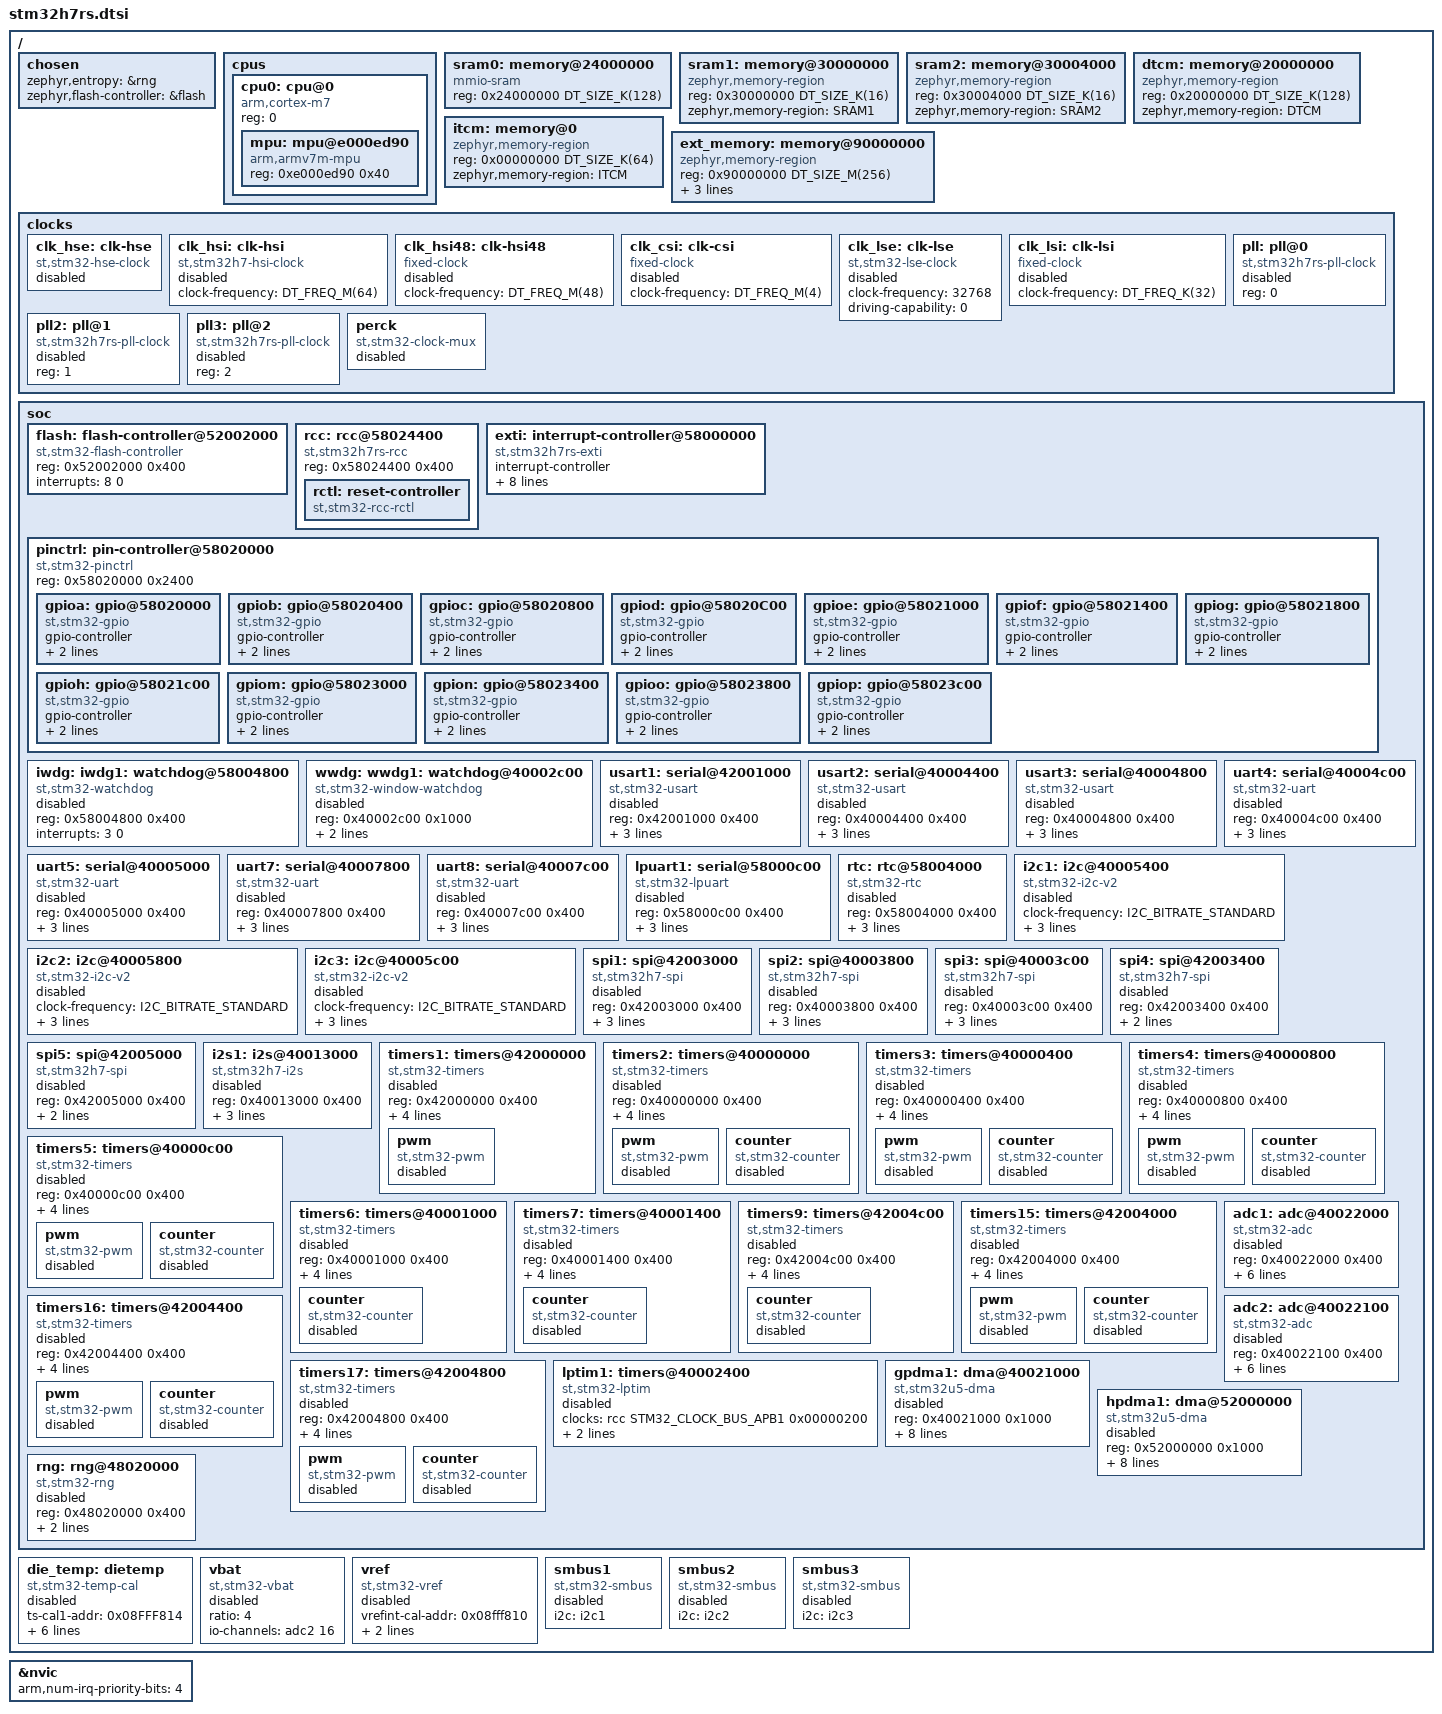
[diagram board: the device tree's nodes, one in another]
/*
 * Copyright (c) 2024 STMicroelectronics
 *
 * SPDX-License-Identifier: Apache-2.0
 */

#include <arm/armv7-m.dtsi>
#include <zephyr/dt-bindings/clock/stm32h7rs_clock.h>
#include <zephyr/dt-bindings/gpio/gpio.h>
#include <zephyr/dt-bindings/i2c/i2c.h>
#include <zephyr/dt-bindings/pwm/pwm.h>
#include <zephyr/dt-bindings/pwm/stm32_pwm.h>
#include <zephyr/dt-bindings/dma/stm32_dma.h>
#include <zephyr/dt-bindings/adc/stm32h7_adc.h>
#include <zephyr/dt-bindings/reset/stm32h7_reset.h>
#include <zephyr/dt-bindings/adc/adc.h>
#include <zephyr/dt-bindings/memory-controller/stm32-fmc-sdram.h>
#include <zephyr/dt-bindings/memory-attr/memory-attr.h>
#include <zephyr/dt-bindings/memory-attr/memory-attr-arm.h>
#include <freq.h>

/*
 * STM32H7RS line contains has many common peripherals with STM32H7.
 */

/ {
	chosen {
		zephyr,entropy = &rng;
		zephyr,flash-controller = &flash;
	};

	cpus {
		#address-cells = <1>;
		#size-cells = <0>;

		cpu0: cpu@0 {
			device_type = "cpu";
			compatible = "arm,cortex-m7";
			reg = <0>;
			#address-cells = <1>;
			#size-cells = <1>;

			mpu: mpu@e000ed90 {
				compatible = "arm,armv7m-mpu";
				reg = <0xe000ed90 0x40>;
			};
		};
	};

	/* System data RAM accessible over AXI bus: AXI SRAM1 in CD domain */
	sram0: memory@24000000 {
		compatible = "mmio-sram";
		reg = <0x24000000 DT_SIZE_K(128)>;
	};

	/* System data RAM accessible over AHB bus: SRAM1 in D2 domain */
	sram1: memory@30000000 {
		reg = <0x30000000 DT_SIZE_K(16)>;
		compatible = "zephyr,memory-region", "mmio-sram";
		zephyr,memory-region = "SRAM1";
	};

	/* System data RAM accessible over AHB bus: SRAM2 in D2 domain */
	sram2: memory@30004000 {
		compatible = "zephyr,memory-region", "mmio-sram";
		reg = <0x30004000 DT_SIZE_K(16)>;
		zephyr,memory-region = "SRAM2";
	};

	dtcm: memory@20000000 {
		compatible = "zephyr,memory-region", "arm,dtcm";
		reg = <0x20000000 DT_SIZE_K(128)>;
		zephyr,memory-region = "DTCM";
	};

	itcm: memory@0 {
		compatible = "zephyr,memory-region", "arm,itcm";
		reg = <0x00000000 DT_SIZE_K(64)>;
		zephyr,memory-region = "ITCM";
	};

	ext_memory: memory@90000000 {
		compatible = "zephyr,memory-region", "mmio-sram";
		reg = <0x90000000 DT_SIZE_M(256)>;
		zephyr,memory-region = "EXTMEM";
		zephyr,memory-attr = <( DT_MEM_ARM(ATTR_MPU_IO) )>;
	};

	clocks {
		#address-cells = <1>;
		#size-cells = <0>;

		clk_hse: clk-hse {
			#clock-cells = <0>;
			compatible = "st,stm32-hse-clock";
			status = "disabled";
		};

		clk_hsi: clk-hsi {
			#clock-cells = <0>;
			compatible = "st,stm32h7-hsi-clock";
			clock-frequency = <DT_FREQ_M(64)>;
			status = "disabled";
		};

		clk_hsi48: clk-hsi48 {
			#clock-cells = <0>;
			compatible = "fixed-clock";
			clock-frequency = <DT_FREQ_M(48)>;
			status = "disabled";
		};

		clk_csi: clk-csi {
			#clock-cells = <0>;
			compatible = "fixed-clock";
			clock-frequency = <DT_FREQ_M(4)>;
			status = "disabled";
		};

		clk_lse: clk-lse {
			#clock-cells = <0>;
			compatible = "st,stm32-lse-clock";
			clock-frequency = <32768>;
			driving-capability = <0>;
			status = "disabled";
		};

		clk_lsi: clk-lsi {
			#clock-cells = <0>;
			compatible = "fixed-clock";
			clock-frequency = <DT_FREQ_K(32)>;
			status = "disabled";
		};

		pll: pll@0 {
			#clock-cells = <0>;
			compatible = "st,stm32h7rs-pll-clock";
			reg = <0>;
			status = "disabled";
		};

		pll2: pll@1 {
			#clock-cells = <0>;
			compatible = "st,stm32h7rs-pll-clock";
			reg = <1>;
			status = "disabled";
		};

		pll3: pll@2 {
			#clock-cells = <0>;
			compatible = "st,stm32h7rs-pll-clock";
			reg = <2>;
			status = "disabled";
		};

		perck: perck {
			#clock-cells = <0>;
			compatible = "st,stm32-clock-mux";
			status = "disabled";
		};
	};

	soc {
		flash: flash-controller@52002000 {
			compatible = "st,stm32-flash-controller", "st,stm32h7-flash-controller";
			reg = <0x52002000 0x400>;
			interrupts = <8 0>;

			#address-cells = <1>;
			#size-cells = <1>;
		};

		rcc: rcc@58024400 {
			compatible = "st,stm32h7rs-rcc";
			#clock-cells = <2>;
			reg = <0x58024400 0x400>;

			rctl: reset-controller {
				compatible = "st,stm32-rcc-rctl";
				#reset-cells = <1>;
			};
		};

		exti: interrupt-controller@58000000 {
			compatible = "st,stm32h7rs-exti", "st,stm32-exti";
			interrupt-controller;
			#interrupt-cells = <1>;
			#address-cells = <1>;
			reg = <0x58000000 0x400>;
			/* SBS for interrupt */
			num-lines = <16>;
			interrupts = <16 0>, <17 0>, <18 0>, <19 0>,
				     <20 0>, <21 0>, <22 0>, <23 0>,
				     <24 0>, <25 0>, <26 0>, <27 0>,
				     <28 0>, <29 0>, <30 0>, <31 0>;
			interrupt-names = "line0", "line1", "line2", "line3",
					  "line4", "line5", "line6", "line7",
					  "line8", "line9", "line10", "line11",
					  "line12", "line13", "line14", "line15";
			line-ranges = <0 1>, <1 1>, <2 1>, <3 1>,
				      <4 1>, <5 1>, <6 1>, <7 1>,
				      <8 1>, <9 1>, <10 1>, <11 1>,
				      <12 1>, <13 1>, <14 1>, <15 1>;
		};

		pinctrl: pin-controller@58020000 {
			compatible = "st,stm32-pinctrl";
			#address-cells = <1>;
			#size-cells = <1>;
			reg = <0x58020000 0x2400>;

			gpioa: gpio@58020000 {
				compatible = "st,stm32-gpio";
				gpio-controller;
				#gpio-cells = <2>;
				reg = <0x58020000 0x400>;
				clocks = <&rcc STM32_CLOCK_BUS_AHB4 0x00000001>;
			};

			gpiob: gpio@58020400 {
				compatible = "st,stm32-gpio";
				gpio-controller;
				#gpio-cells = <2>;
				reg = <0x58020400 0x400>;
				clocks = <&rcc STM32_CLOCK_BUS_AHB4 0x00000002>;
			};

			gpioc: gpio@58020800 {
				compatible = "st,stm32-gpio";
				gpio-controller;
				#gpio-cells = <2>;
				reg = <0x58020800 0x400>;
				clocks = <&rcc STM32_CLOCK_BUS_AHB4 0x00000004>;
			};

			gpiod: gpio@58020C00 {
				compatible = "st,stm32-gpio";
				gpio-controller;
				#gpio-cells = <2>;
				reg = <0x58020C00 0x400>;
				clocks = <&rcc STM32_CLOCK_BUS_AHB4 0x00000008>;
			};

			gpioe: gpio@58021000 {
				compatible = "st,stm32-gpio";
				gpio-controller;
				#gpio-cells = <2>;
				reg = <0x58021000 0x400>;
				clocks = <&rcc STM32_CLOCK_BUS_AHB4 0x00000010>;
			};

			gpiof: gpio@58021400 {
				compatible = "st,stm32-gpio";
				gpio-controller;
				#gpio-cells = <2>;
				reg = <0x58021400 0x400>;
				clocks = <&rcc STM32_CLOCK_BUS_AHB4 0x00000020>;
			};

			gpiog: gpio@58021800 {
				compatible = "st,stm32-gpio";
				gpio-controller;
				#gpio-cells = <2>;
				reg = <0x58021800 0x400>;
				clocks = <&rcc STM32_CLOCK_BUS_AHB4 0x00000040>;
			};

			gpioh: gpio@58021c00 {
				compatible = "st,stm32-gpio";
				gpio-controller;
				#gpio-cells = <2>;
				reg = <0x58021c00 0x400>;
				clocks = <&rcc STM32_CLOCK_BUS_AHB4 0x00000080>;
			};

			gpiom: gpio@58023000 {
				compatible = "st,stm32-gpio";
				gpio-controller;
				#gpio-cells = <2>;
				reg = <0x58023000 0x400>;
				clocks = <&rcc STM32_CLOCK_BUS_AHB4 0x00001000>;
			};

			gpion: gpio@58023400 {
				compatible = "st,stm32-gpio";
				gpio-controller;
				#gpio-cells = <2>;
				reg = <0x58023400 0x400>;
				clocks = <&rcc STM32_CLOCK_BUS_AHB4 0x00002000>;
			};

			gpioo: gpio@58023800 {
				compatible = "st,stm32-gpio";
				gpio-controller;
				#gpio-cells = <2>;
				reg = <0x58023800 0x400>;
				clocks = <&rcc STM32_CLOCK_BUS_AHB4 0x00004000>;
			};

			gpiop: gpio@58023c00 {
				compatible = "st,stm32-gpio";
				gpio-controller;
				#gpio-cells = <2>;
				reg = <0x58023c00 0x400>;
				clocks = <&rcc STM32_CLOCK_BUS_AHB4 0x00008000>;
			};
		};

		iwdg: iwdg1: watchdog@58004800 {
			compatible = "st,stm32-watchdog";
			reg = <0x58004800 0x400>;
			interrupts = <3 0>;
			status = "disabled";
		};

		wwdg: wwdg1: watchdog@40002c00 {
			compatible = "st,stm32-window-watchdog";
			reg = <0x40002c00 0x1000>;
			clocks = <&rcc STM32_CLOCK_BUS_APB1 0x00000800>;
			interrupts = <4 7>;
			status = "disabled";
		};

		usart1: serial@42001000 {
			compatible = "st,stm32-usart", "st,stm32-uart";
			reg = <0x42001000 0x400>;
			clocks = <&rcc STM32_CLOCK_BUS_APB2 0x00000010>;
			resets = <&rctl STM32_RESET(APB2, 4U)>;
			interrupts = <82 0>;
			status = "disabled";
		};
		usart2: serial@40004400 {
			compatible = "st,stm32-usart", "st,stm32-uart";
			reg = <0x40004400 0x400>;
			clocks = <&rcc STM32_CLOCK_BUS_APB1 0x00020000>;
			resets = <&rctl STM32_RESET(APB1L, 17U)>;
			interrupts = <83 0>;
			status = "disabled";
		};
		usart3: serial@40004800 {
			compatible = "st,stm32-usart", "st,stm32-uart";
			reg = <0x40004800 0x400>;
			clocks = <&rcc STM32_CLOCK_BUS_APB1 0x00040000>;
			resets = <&rctl STM32_RESET(APB1L, 18U)>;
			interrupts = <84 0>;
			status = "disabled";
		};
		uart4: serial@40004c00 {
			compatible ="st,stm32-uart";
			reg = <0x40004c00 0x400>;
			clocks = <&rcc STM32_CLOCK_BUS_APB1 0x00080000>;
			resets = <&rctl STM32_RESET(APB1L, 19U)>;
			interrupts = <85 0>;
			status = "disabled";
		};
		uart5: serial@40005000 {
			compatible = "st,stm32-uart";
			reg = <0x40005000 0x400>;
			clocks = <&rcc STM32_CLOCK_BUS_APB1 0x00100000>;
			resets = <&rctl STM32_RESET(APB1L, 20U)>;
			interrupts = <86 0>;
			status = "disabled";
		};
		uart7: serial@40007800 {
			compatible = "st,stm32-uart";
			reg = <0x40007800 0x400>;
			clocks = <&rcc STM32_CLOCK_BUS_APB1 0x40000000>;
			resets = <&rctl STM32_RESET(APB1L, 30U)>;
			interrupts = <87 0>;
			status = "disabled";
		};
		uart8: serial@40007c00 {
			compatible = "st,stm32-uart";
			reg = <0x40007c00 0x400>;
			clocks = <&rcc STM32_CLOCK_BUS_APB1 0x80000000>;
			resets = <&rctl STM32_RESET(APB1L, 31U)>;
			interrupts = <88 0>;
			status = "disabled";
		};

		lpuart1: serial@58000c00 {
			compatible = "st,stm32-lpuart", "st,stm32-uart";
			reg = <0x58000c00 0x400>;
			clocks = <&rcc STM32_CLOCK_BUS_APB4 0x00000008>;
			resets = <&rctl STM32_RESET(APB4, 3U)>;
			interrupts = <131 0>;
			status = "disabled";
		};

		rtc: rtc@58004000 {
			compatible = "st,stm32-rtc";
			reg = <0x58004000 0x400>;
			interrupts = <32 0>;
			clocks = <&rcc STM32_CLOCK_BUS_APB4 0x00010000>;
			prescaler = <32768>;
			status = "disabled";
		};

		i2c1: i2c@40005400 {
			compatible = "st,stm32-i2c-v2";
			clock-frequency = <I2C_BITRATE_STANDARD>;
			#address-cells = <1>;
			#size-cells = <0>;
			reg = <0x40005400 0x400>;
			clocks = <&rcc STM32_CLOCK_BUS_APB1 0x00200000>;
			interrupts = <76 0>, <77 0>;
			interrupt-names = "event", "error";
			status = "disabled";
		};

		i2c2: i2c@40005800 {
			compatible = "st,stm32-i2c-v2";
			clock-frequency = <I2C_BITRATE_STANDARD>;
			#address-cells = <1>;
			#size-cells = <0>;
			reg = <0x40005800 0x400>;
			clocks = <&rcc STM32_CLOCK_BUS_APB1 0x00400000>;
			interrupts = <78 0>, <79 0>;
			interrupt-names = "event", "error";
			status = "disabled";
		};

		i2c3: i2c@40005c00 {
			compatible = "st,stm32-i2c-v2";
			clock-frequency = <I2C_BITRATE_STANDARD>;
			#address-cells = <1>;
			#size-cells = <0>;
			reg = <0x40005c00 0x400>;
			clocks = <&rcc STM32_CLOCK_BUS_APB1 0x00800000>;
			interrupts = <80 0>, <81 0>;
			interrupt-names = "event", "error";
			status = "disabled";
		};

		spi1: spi@42003000 {
			compatible = "st,stm32h7-spi", "st,stm32-spi-fifo", "st,stm32-spi";
			#address-cells = <1>;
			#size-cells = <0>;
			reg = <0x42003000 0x400>;
			clocks = <&rcc STM32_CLOCK_BUS_APB2 0x00001000>,
				<&rcc STM32_SRC_PLL1_Q SPI1_SEL(0)>;
			interrupts = <58 0>;
			status = "disabled";
		};

		spi2: spi@40003800 {
			compatible = "st,stm32h7-spi", "st,stm32-spi-fifo", "st,stm32-spi";
			#address-cells = <1>;
			#size-cells = <0>;
			reg = <0x40003800 0x400>;
			clocks = <&rcc STM32_CLOCK_BUS_APB1 0x00004000>,
				<&rcc STM32_SRC_PLL1_Q SPI23_SEL(0)>;
			interrupts = <59 0>;
			status = "disabled";
		};

		spi3: spi@40003c00 {
			compatible = "st,stm32h7-spi", "st,stm32-spi-fifo", "st,stm32-spi";
			#address-cells = <1>;
			#size-cells = <0>;
			reg = <0x40003c00 0x400>;
			clocks = <&rcc STM32_CLOCK_BUS_APB1 0x00008000>,
				<&rcc STM32_SRC_PLL1_Q SPI23_SEL(0)>;
			interrupts = <60 0>;
			status = "disabled";
		};

		spi4: spi@42003400 {
			compatible = "st,stm32h7-spi", "st,stm32-spi-fifo", "st,stm32-spi";
			#address-cells = <1>;
			#size-cells = <0>;
			reg = <0x42003400 0x400>;
			clocks = <&rcc STM32_CLOCK_BUS_APB2 0x00002000>;
			interrupts = <61 0>;
			status = "disabled";
		};

		spi5: spi@42005000 {
			compatible = "st,stm32h7-spi", "st,stm32-spi-fifo", "st,stm32-spi";
			#address-cells = <1>;
			#size-cells = <0>;
			reg = <0x42005000 0x400>;
			clocks = <&rcc STM32_CLOCK_BUS_APB2 0x00100000>;
			interrupts = <62 0>;
			status = "disabled";
		};

		i2s1: i2s@40013000 {
			compatible = "st,stm32h7-i2s", "st,stm32-i2s";
			#address-cells = <1>;
			#size-cells = <0>;
			reg = <0x40013000 0x400>;
			clocks = <&rcc STM32_CLOCK_BUS_APB2 0x00001000>,
				 <&rcc STM32_SRC_PLL1_Q SPI1_SEL(0)>;
/*			dmas = <&dmamux1 0 38 (STM32_DMA_PERIPH_TX | STM32_DMA_PRIORITY_HIGH)
				&dmamux1 1 37 (STM32_DMA_PERIPH_RX | STM32_DMA_PRIORITY_HIGH)>;*/
			dma-names = "tx", "rx";
			interrupts = <35 3>;
			status = "disabled";
		};
/*
		i2s2: i2s@40003800 {
			compatible = "st,stm32h7-i2s", "st,stm32-i2s";
			#address-cells = <1>;
			#size-cells = <0>;
			reg = <0x40003800 0x400>;
			clocks = <&rcc STM32_CLOCK_BUS_APB1 0x00004000>,
				 <&rcc STM32_SRC_PLL1_Q SPI123_SEL(0)>;
			dmas = <&dmamux1 0 40 (STM32_DMA_PERIPH_TX | STM32_DMA_PRIORITY_HIGH)
				&dmamux1 1 39 (STM32_DMA_PERIPH_RX | STM32_DMA_PRIORITY_HIGH)>;
			dma-names = "tx", "rx";
			interrupts = <36 0>;
			status = "disabled";
		};

		i2s3: i2s@40003c00 {
			compatible = "st,stm32h7-i2s", "st,stm32-i2s";
			#address-cells = <1>;
			#size-cells = <0>;
			reg = <0x40003c00 0x400>;
			clocks = <&rcc STM32_CLOCK_BUS_APB1 0x00008000>,
				 <&rcc STM32_SRC_PLL1_Q SPI123_SEL(0)>;
			dmas = <&dmamux1 0 62 (STM32_DMA_PERIPH_TX | STM32_DMA_PRIORITY_HIGH)
				&dmamux1 1 61 (STM32_DMA_PERIPH_RX | STM32_DMA_PRIORITY_HIGH)>;
			dma-names = "tx", "rx";
			interrupts = <51 0>;
			status = "disabled";
		};

		fdcan1: can@4000a000 {
			compatible = "st,stm32h7-fdcan";
			reg = <0x4000a000 0x400>, <0x4000ac00 0x350>;
			reg-names = "m_can", "message_ram";
			clocks = <&rcc STM32_CLOCK_BUS_APB1_2 0x00000100>;
			interrupts = <19 0>, <21 0>, <63 0>;
			interrupt-names = "int0", "int1", "calib";
			bosch,mram-cfg = <0x0 28 8 3 3 0 3 3>;
			sample-point = <875>;
			sample-point-data = <875>;
			status = "disabled";
		};

		fdcan2: can@4000a400 {
			compatible = "st,stm32h7-fdcan";
			reg = <0x4000a400 0x400>, <0x4000ac00 0x6a0>;
			reg-names = "m_can", "message_ram";
			clocks = <&rcc STM32_CLOCK_BUS_APB1_2 0x00000100>;
			interrupts = <20 0>, <22 0>, <63 0>;
			interrupt-names = "int0", "int1", "calib";
			bosch,mram-cfg = <0x350 28 8 3 3 0 3 3>;
			sample-point = <875>;
			sample-point-data = <875>;
			status = "disabled";
		};
*/
		timers1: timers@42000000 {
			compatible = "st,stm32-timers";
			reg = <0x42000000 0x400>;
			clocks = <&rcc STM32_CLOCK_BUS_APB2 0x00000001>;
			resets = <&rctl STM32_RESET(APB2, 0U)>;
			interrupts = <47 0>, <48 0>, <49 0>, <50 0>;
			interrupt-names = "brk", "up", "trgcom", "cc";
			st,prescaler = <0>;
			status = "disabled";

			pwm {
				compatible = "st,stm32-pwm";
				status = "disabled";
				#pwm-cells = <3>;
			};
		};

		timers2: timers@40000000 {
			compatible = "st,stm32-timers";
			reg = <0x40000000 0x400>;
			clocks = <&rcc STM32_CLOCK_BUS_APB1 0x00000001>;
			resets = <&rctl STM32_RESET(APB1L, 0U)>;
			interrupts = <51 0>;
			interrupt-names = "global";
			st,prescaler = <0>;
			status = "disabled";

			pwm {
				compatible = "st,stm32-pwm";
				status = "disabled";
				#pwm-cells = <3>;
			};

			counter {
				compatible = "st,stm32-counter";
				status = "disabled";
			};
		};

		timers3: timers@40000400 {
			compatible = "st,stm32-timers";
			reg = <0x40000400 0x400>;
			clocks = <&rcc STM32_CLOCK_BUS_APB1 0x00000002>;
			resets = <&rctl STM32_RESET(APB1L, 1U)>;
			interrupts = <52 0>;
			interrupt-names = "global";
			st,prescaler = <0>;
			status = "disabled";

			pwm {
				compatible = "st,stm32-pwm";
				status = "disabled";
				#pwm-cells = <3>;
			};

			counter {
				compatible = "st,stm32-counter";
				status = "disabled";
			};
		};

		timers4: timers@40000800 {
			compatible = "st,stm32-timers";
			reg = <0x40000800 0x400>;
			clocks = <&rcc STM32_CLOCK_BUS_APB1 0x00000004>;
			resets = <&rctl STM32_RESET(APB1L, 2U)>;
			interrupts = <53 0>;
			interrupt-names = "global";
			st,prescaler = <0>;
			status = "disabled";

			pwm {
				compatible = "st,stm32-pwm";
				status = "disabled";
				#pwm-cells = <3>;
			};

			counter {
				compatible = "st,stm32-counter";
				status = "disabled";
			};
		};

		timers5: timers@40000c00 {
			compatible = "st,stm32-timers";
			reg = <0x40000c00 0x400>;
			clocks = <&rcc STM32_CLOCK_BUS_APB1 0x00000008>;
			resets = <&rctl STM32_RESET(APB1L, 3U)>;
			interrupts = <54 0>;
			interrupt-names = "global";
			st,prescaler = <0>;
			status = "disabled";

			pwm {
				compatible = "st,stm32-pwm";
				status = "disabled";
				#pwm-cells = <3>;
			};

			counter {
				compatible = "st,stm32-counter";
				status = "disabled";
			};
		};

		timers6: timers@40001000 {
			compatible = "st,stm32-timers";
			reg = <0x40001000 0x400>;
			clocks = <&rcc STM32_CLOCK_BUS_APB1 0x00000010>;
			resets = <&rctl STM32_RESET(APB1L, 4U)>;
			interrupts = <55 0>;
			interrupt-names = "global";
			st,prescaler = <0>;
			status = "disabled";

			counter {
				compatible = "st,stm32-counter";
				status = "disabled";
			};
		};

		timers7: timers@40001400 {
			compatible = "st,stm32-timers";
			reg = <0x40001400 0x400>;
			clocks = <&rcc STM32_CLOCK_BUS_APB1 0x00000020>;
			resets = <&rctl STM32_RESET(APB1L, 5U)>;
			interrupts = <56 0>;
			interrupt-names = "global";
			st,prescaler = <0>;
			status = "disabled";

			counter {
				compatible = "st,stm32-counter";
				status = "disabled";
			};
		};

		timers9: timers@42004c00 {
			compatible = "st,stm32-timers";
			reg = <0x42004c00 0x400>;
			clocks = <&rcc STM32_CLOCK_BUS_APB2 0x00080000>;
			resets = <&rctl STM32_RESET(APB2, 19U)>;
			interrupts = <57 0>;
			interrupt-names = "global";
			st,prescaler = <0>;
			status = "disabled";

			counter {
				compatible = "st,stm32-counter";
				status = "disabled";
			};
		};

		timers15: timers@42004000 {
			compatible = "st,stm32-timers";
			reg = <0x42004000 0x400>;
			clocks = <&rcc STM32_CLOCK_BUS_APB2 0x00010000>;
			resets = <&rctl STM32_RESET(APB2, 16U)>;
			interrupts = <116 0>;
			interrupt-names = "global";
			st,prescaler = <0>;
			status = "disabled";

			pwm {
				compatible = "st,stm32-pwm";
				status = "disabled";
				#pwm-cells = <3>;
			};

			counter {
				compatible = "st,stm32-counter";
				status = "disabled";
			};
		};

		timers16: timers@42004400 {
			compatible = "st,stm32-timers";
			reg = <0x42004400 0x400>;
			clocks = <&rcc STM32_CLOCK_BUS_APB1 0x00020000>;
			resets = <&rctl STM32_RESET(APB2, 17U)>;
			interrupts = <117 0>;
			interrupt-names = "global";
			st,prescaler = <0>;
			status = "disabled";

			pwm {
				compatible = "st,stm32-pwm";
				status = "disabled";
				#pwm-cells = <3>;
			};

			counter {
				compatible = "st,stm32-counter";
				status = "disabled";
			};
		};

		timers17: timers@42004800 {
			compatible = "st,stm32-timers";
			reg = <0x42004800 0x400>;
			clocks = <&rcc STM32_CLOCK_BUS_APB1 0x00040000>;
			resets = <&rctl STM32_RESET(APB2, 18U)>;
			interrupts = <118 0>;
			interrupt-names = "global";
			st,prescaler = <0>;
			status = "disabled";

			pwm {
				compatible = "st,stm32-pwm";
				status = "disabled";
				#pwm-cells = <3>;
			};

			counter {
				compatible = "st,stm32-counter";
				status = "disabled";
			};
		};

		lptim1: timers@40002400 {
			compatible = "st,stm32-lptim";
			clocks = <&rcc STM32_CLOCK_BUS_APB1 0x00000200>;
			#address-cells = <1>;
			#size-cells = <0>;
			reg = <0x40002400 0x400>;
			interrupts = <119 1>;
			interrupt-names = "wakeup";
			status = "disabled";
		};


		adc1: adc@40022000 {
			compatible = "st,stm32-adc";
			reg = <0x40022000 0x400>;
			clocks = <&rcc STM32_CLOCK_BUS_AHB1 0x00000020>;
			interrupts = <38 0>;
			status = "disabled";
			#io-channel-cells = <1>;
			resolutions = <STM32_ADC_RES(12, 0x00)
				       STM32_ADC_RES(10, 0x01)
				       STM32_ADC_RES(8, 0x2)
				       STM32_ADC_RES(6, 0x3)>;
			sampling-times = <3 7 13 25 48 93 248 641>;
			st,adc-sequencer = <FULLY_CONFIGURABLE>;
		};

		adc2: adc@40022100 {
			compatible = "st,stm32-adc";
			reg = <0x40022100 0x400>;
			clocks = <&rcc STM32_CLOCK_BUS_AHB1 0x00000020>;
			interrupts = <38 0>;
			status = "disabled";
			#io-channel-cells = <1>;
			resolutions = <STM32_ADC_RES(12, 0x00)
				       STM32_ADC_RES(10, 0x01)
				       STM32_ADC_RES(8, 0x02)
				       STM32_ADC_RES(6, 0x03)>;
			sampling-times = <3 7 13 25 48 93 248 641>;
			st,adc-sequencer = <FULLY_CONFIGURABLE>;
		};

		/* dual mode: adc1 and adc2 coupled */
/*		adc1_2: adc@40022300 {
			compatible = "st,stm32-adc";
			reg = <0x40022300 0x400>;
			clocks = <&rcc STM32_CLOCK_BUS_AHB1 0x00000020>;
			interrupts = <18 0>;
			status = "disabled";
			#io-channel-cells = <1>;
			resolutions = <STM32_ADC_RES(16, 0x00)
				       STM32_ADC_RES(14, 0x05)
				       STM32_ADC_RES(12, 0x06)
				       STM32_ADC_RES(10, 0x03)
				       STM32_ADC_RES(8, 0x07)>;
			sampling-times = <2 3 9 17 33 65 388 811>;
			st,adc-sequencer = <FULLY_CONFIGURABLE>;
		};
*/

		gpdma1: dma@40021000 {
			compatible = "st,stm32u5-dma";
			#dma-cells = <3>;
			reg = <0x40021000 0x1000>;
			interrupts = <39 0>, <40 0>, <41 0>, <42 0>,
					<43 0>, <44 0>, <45 0>, <46 0>,
					<133 0>, <134 0>, <135 0>, <136 0>,
					<137 0>, <138 0>, <139 0>, <140 0>;
			clocks = <&rcc STM32_CLOCK_BUS_AHB1 0x00000010>;
			st,mem2mem;
			dma-channels = <16>;
			dma-offset = <0>;
			dma-requests = <110>;
			status = "disabled";
		};

		hpdma1: dma@52000000 {
			compatible = "st,stm32u5-dma";
			#dma-cells = <3>;
			reg = <0x52000000 0x1000>;
			interrupts = <64 0>, <65 0>, <66 0>, <67 0>,
					<68 0>, <69 0>, <70 0>, <71 0>,
					<141 0>, <142 0>, <143 0>, <144 0>,
					<145 0>, <146 0>, <147 0>, <148 0>;
			clocks = <&rcc STM32_CLOCK_BUS_AHB5 0x00000001>;
			st,mem2mem;
			dma-channels = <16>;
			dma-offset = <0>;
			dma-requests = <20>;
			status = "disabled";
		};

		rng: rng@48020000 {
			compatible = "st,stm32-rng";
			reg = <0x48020000 0x400>;
			clocks = <&rcc STM32_CLOCK_BUS_AHB3 0x00000001>;
			interrupts = <37 0>;
			status = "disabled";
		};
/*
		sdmmc1: sdmmc@52007000 {
			compatible = "st,stm32-sdmmc";
			reg = <0x52007000 0x400>;
			clocks = <&rcc STM32_CLOCK_BUS_AHB5 0x00000100>,
				 <&rcc STM32_SRC_PLL1_Q SDMMC_SEL(0)>;
			resets = <&rctl STM32_RESET(AHB5, 8U)>;
			interrupts = <108 0>;
			status = "disabled";
		};

		sdmmc2: sdmmc@48022400 {
			compatible = "st,stm32-sdmmc";
			reg = <0x48022400 0x400>;
			clocks = <&rcc STM32_CLOCK_BUS_AHB2 0x00000200>,
				 <&rcc STM32_SRC_PLL1_Q SDMMC_SEL(0)>;
			resets = <&rctl STM32_RESET(AHB2, 9U)>;
			interrupts = <109 0>;
			status = "disabled";
		};
*/
/*
		mac: ethernet@40028000 {
			compatible = "st,stm32-ethernet";
			reg = <0x40028000 0x8000>;
			interrupts = <61 0>;
			clock-names = "stmmaceth", "mac-clk-tx", "mac-clk-rx";
			clocks = <&rcc STM32_CLOCK_BUS_AHB1 0x00008000>,
				 <&rcc STM32_CLOCK_BUS_AHB1 0x00010000>,
				 <&rcc STM32_CLOCK_BUS_AHB1 0x00020000>;
			status = "disabled";
		};

		fmc: memory-controller@52004000 {
			compatible = "st,stm32h7-fmc";
			reg = <0x52004000 0x400>;
			clocks = <&rcc STM32_CLOCK_BUS_AHB3 0x00001000>;
			status = "disabled";

			sdram: sdram {
				compatible = "st,stm32-fmc-sdram";
				#address-cells = <1>;
				#size-cells = <0>;
				status = "disabled";
			};
		};

		backup_sram: memory@38800000 {
			compatible = "zephyr,memory-region", "st,stm32-backup-sram";
			reg = <0x38800000 DT_SIZE_K(4)>;
			clocks = <&rcc STM32_CLOCK_BUS_AHB4 0x10000000>;
			zephyr,memory-region = "BACKUP_SRAM";
			status = "disabled";
		};

		quadspi: quadspi@52005000 {
			compatible = "st,stm32-qspi";
			#address-cells = <0x1>;
			#size-cells = <0x0>;
			reg = <0x52005000 0x34>;
			interrupts = <92 0>;
			clocks = <&rcc STM32_CLOCK_BUS_AHB3 0x00004000>;
			status = "disabled";
		};
*/
	};

	die_temp: dietemp {
		compatible = "st,stm32-temp-cal";
		ts-cal1-addr = <0x08FFF814>;
		ts-cal2-addr = <0x08FFF818>;
		ts-cal1-temp = <30>;
		ts-cal2-temp = <130>;
		ts-cal-vrefanalog = <3300>;
		ts-cal-resolution = <12>;
		io-channels = <&adc1 16>;
		status = "disabled";
	};

	vbat: vbat {
		compatible = "st,stm32-vbat";
		ratio = <4>;
		status = "disabled";
		io-channels = <&adc2 16>;
	};

	vref: vref {
		compatible = "st,stm32-vref";
		vrefint-cal-addr = <0x08fff810>;
		vrefint-cal-mv = <3300>;
		status = "disabled";
		io-channels = <&adc1 17>;
	};

	smbus1: smbus1 {
		compatible = "st,stm32-smbus";
		#address-cells = <1>;
		#size-cells = <0>;
		i2c = <&i2c1>;
		status = "disabled";
	};

	smbus2: smbus2 {
		compatible = "st,stm32-smbus";
		#address-cells = <1>;
		#size-cells = <0>;
		i2c = <&i2c2>;
		status = "disabled";
	};

	smbus3: smbus3 {
		compatible = "st,stm32-smbus";
		#address-cells = <1>;
		#size-cells = <0>;
		i2c = <&i2c3>;
		status = "disabled";
	};
};

&nvic {
	arm,num-irq-priority-bits = <4>;
};
